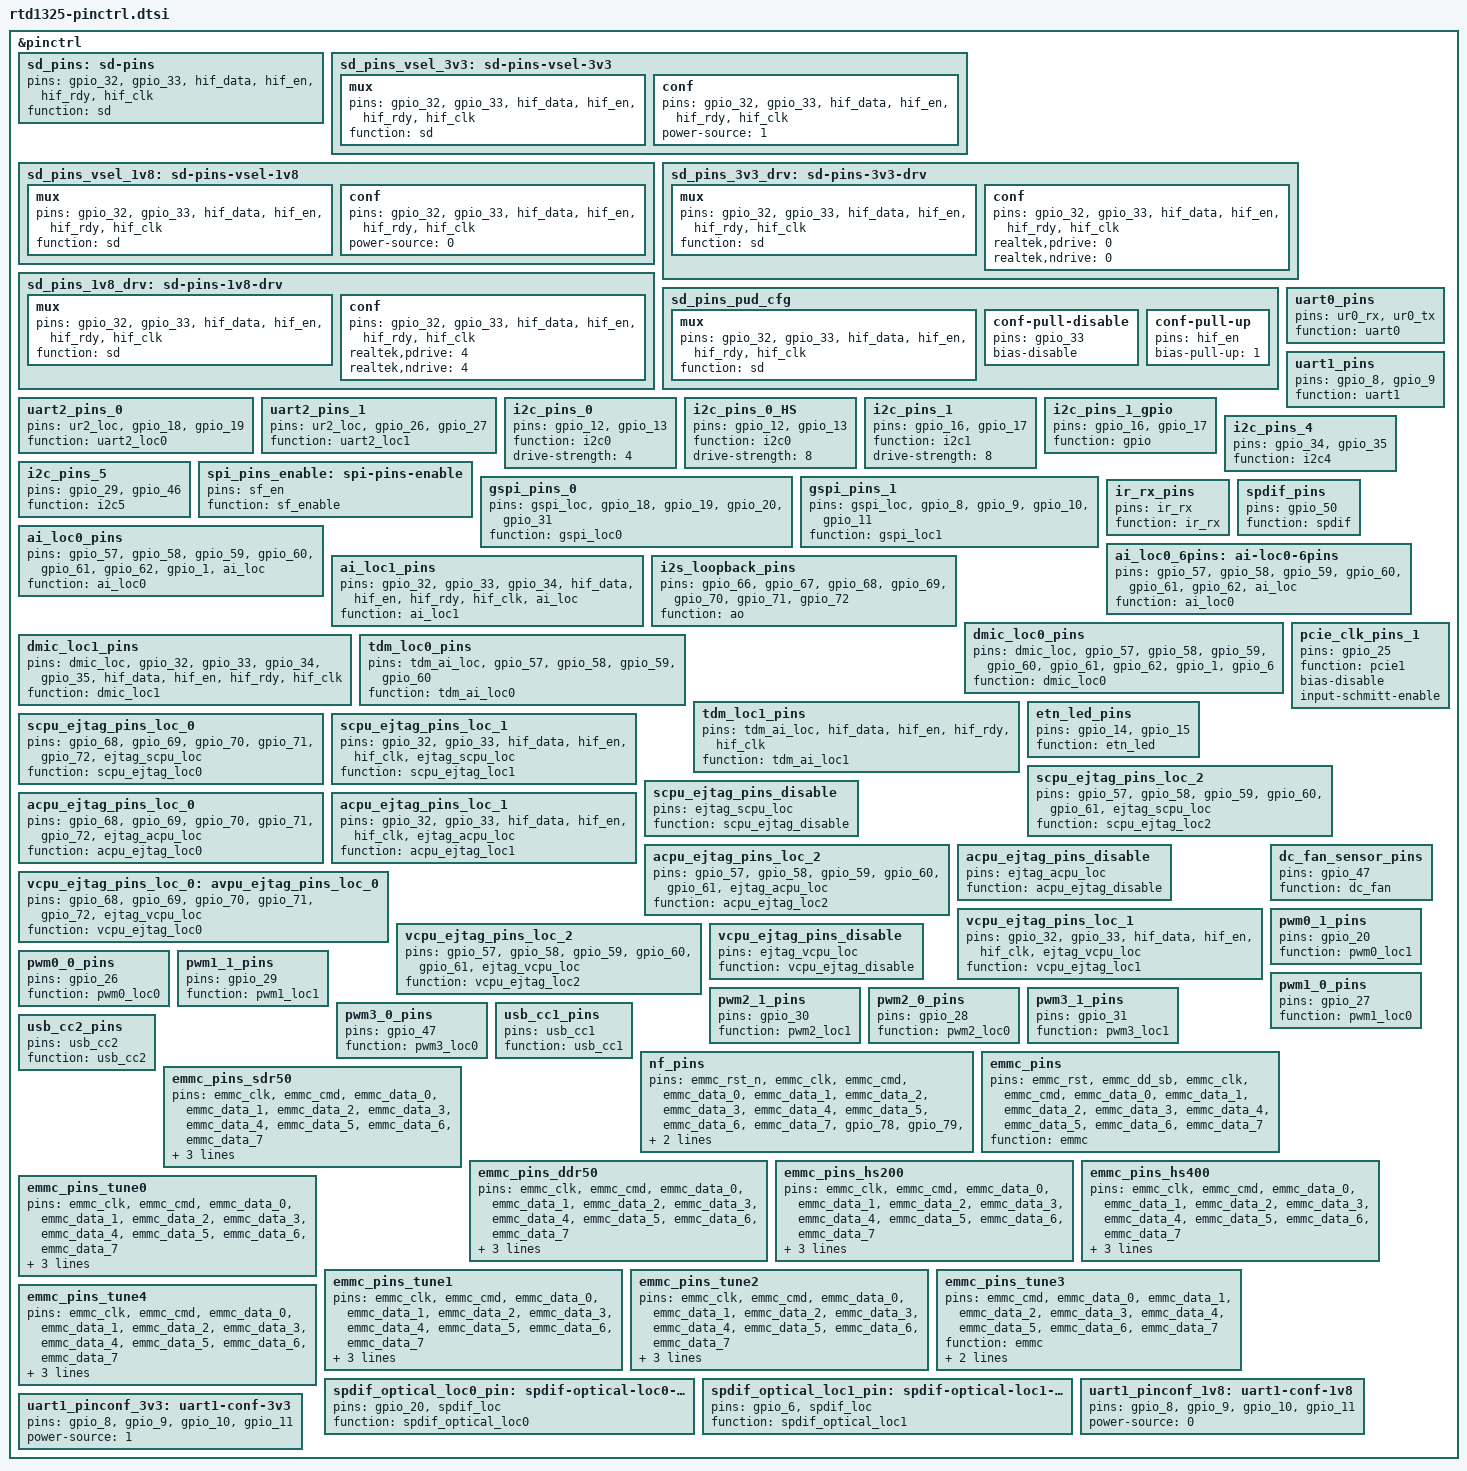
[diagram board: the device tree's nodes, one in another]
// SPDX-License-Identifier: (GPL-2.0-or-later OR BSD-2-Clause)
/*
 * Copyright (c) 2022 Realtek Semiconductor Corp.
 */

&pinctrl {
	sd_pins: sd-pins {
		pins = "gpio_32", "gpio_33", "hif_data", "hif_en", "hif_rdy", "hif_clk";
		function = "sd";
	};

	sd_pins_vsel_3v3: sd-pins-vsel-3v3 {
		mux {
			pins = "gpio_32", "gpio_33", "hif_data", "hif_en", "hif_rdy", "hif_clk";
			function = "sd";
		};

		conf {
			pins = "gpio_32", "gpio_33", "hif_data", "hif_en", "hif_rdy", "hif_clk";
			power-source = <1>;
		};
	};

	sd_pins_vsel_1v8: sd-pins-vsel-1v8 {
		mux {
			pins = "gpio_32", "gpio_33", "hif_data", "hif_en", "hif_rdy", "hif_clk";
			function = "sd";
		};

		conf {
			pins = "gpio_32", "gpio_33", "hif_data", "hif_en", "hif_rdy", "hif_clk";
			power-source = <0>;
		};
	};

	sd_pins_3v3_drv: sd-pins-3v3-drv {
		mux {
			pins = "gpio_32", "gpio_33", "hif_data", "hif_en", "hif_rdy", "hif_clk";
			function = "sd";
		};

		conf {
			pins = "gpio_32", "gpio_33", "hif_data", "hif_en", "hif_rdy", "hif_clk";
			realtek,pdrive = <0>;
			realtek,ndrive = <0>;
		};
	};

	sd_pins_1v8_drv: sd-pins-1v8-drv {
		mux {
			pins = "gpio_32", "gpio_33", "hif_data", "hif_en", "hif_rdy", "hif_clk";
			function = "sd";
		};

		conf {
			pins = "gpio_32", "gpio_33", "hif_data", "hif_en", "hif_rdy", "hif_clk";
			realtek,pdrive = <4>;
			realtek,ndrive = <4>;
		};
	};

	sd_pins_pud_cfg: sd_pins_pud_cfg {
		mux {
			pins = "gpio_32", "gpio_33", "hif_data", "hif_en", "hif_rdy", "hif_clk";
			function = "sd";
		};

		conf-pull-disable {
			pins = "gpio_33";
			bias-disable;
		};

		conf-pull-up {
			pins = "hif_en";
			bias-pull-up = <1>;
		};
	};

	uart0_pins: uart0_pins {
		pins = "ur0_rx",
			"ur0_tx";
		function = "uart0";
	};

	uart1_pins: uart1_pins {
		pins = "gpio_8",
			"gpio_9";
		function = "uart1";
	};

	uart2_pins_0: uart2_pins_0 {
		pins = "ur2_loc",
			"gpio_18",
			"gpio_19";
		function = "uart2_loc0";
	};

	uart2_pins_1: uart2_pins_1 {
		pins ="ur2_loc",
			"gpio_26",
			"gpio_27";
		function = "uart2_loc1";
	};

	i2c_pins_0: i2c_pins_0 {
		pins = "gpio_12",
			"gpio_13";
		function = "i2c0";
		drive-strength = <4>;
	};

	i2c_pins_0_HS: i2c_pins_0_HS {
		pins = "gpio_12",
			"gpio_13";
		function = "i2c0";
		drive-strength = <8>;
	};

	i2c_pins_1: i2c_pins_1 {
		pins = "gpio_16",
			"gpio_17";
		function = "i2c1";
		drive-strength = <8>;
	};

	i2c_pins_1_gpio: i2c_pins_1_gpio {
		pins = "gpio_16",
			"gpio_17";
		function = "gpio";
	};

	i2c_pins_4: i2c_pins_4 {
		pins = "gpio_34",
			"gpio_35";
		function = "i2c4";
	};

	i2c_pins_5: i2c_pins_5 {
		pins = "gpio_29",
			"gpio_46";
		function = "i2c5";
	};

	spi_pins_enable: spi-pins-enable {
		pins = "sf_en";
		function = "sf_enable";
	};

	gspi_pins_0: gspi_pins_0 {
		pins = "gspi_loc",
			"gpio_18",
			"gpio_19",
			"gpio_20",
			"gpio_31";
		function = "gspi_loc0";
	};

	gspi_pins_1: gspi_pins_1 {
		pins = "gspi_loc",
			"gpio_8",
			"gpio_9",
			"gpio_10",
			"gpio_11";
		function = "gspi_loc1";
	};

	ir_rx_pins: ir_rx_pins {
		pins = "ir_rx";
		function = "ir_rx";
	};

	spdif_pins: spdif_pins {
		pins = "gpio_50";
		function = "spdif";
	};

	ai_loc0_pins: ai_loc0_pins {
		pins = "gpio_57",
			"gpio_58",
			"gpio_59",
			"gpio_60",
			"gpio_61",
			"gpio_62",
			"gpio_1",
			"ai_loc";
		function = "ai_loc0";
	};

	ai_loc0_6pins: ai-loc0-6pins {
		pins = "gpio_57",
			"gpio_58",
			"gpio_59",
			"gpio_60",
			"gpio_61",
			"gpio_62",
			"ai_loc";
		function = "ai_loc0";
	};

	ai_loc1_pins: ai_loc1_pins {
		pins = "gpio_32",
			"gpio_33",
			"gpio_34",
			"hif_data",
			"hif_en",
			"hif_rdy",
			"hif_clk",
			"ai_loc";
		function = "ai_loc1";
	};

	i2s_loopback_pins: i2s_loopback_pins {
		pins = "gpio_66",
			"gpio_67",
			"gpio_68",
			"gpio_69",
			"gpio_70",
			"gpio_71",
			"gpio_72";
		function = "ao";
	};

	dmic_loc0_pins: dmic_loc0_pins {
		pins = "dmic_loc",
			"gpio_57",
			"gpio_58",
			"gpio_59",
			"gpio_60",
			"gpio_61",
			"gpio_62",
			"gpio_1",
			"gpio_6";
		function = "dmic_loc0";
	};

	dmic_loc1_pins: dmic_loc1_pins {
		pins = "dmic_loc",
			"gpio_32",
			"gpio_33",
			"gpio_34",
			"gpio_35",
			"hif_data",
			"hif_en",
			"hif_rdy",
			"hif_clk";
		function = "dmic_loc1";
	};

	tdm_loc0_pins: tdm_loc0_pins {
		pins = "tdm_ai_loc",
			"gpio_57",
			"gpio_58",
			"gpio_59",
			"gpio_60";
		function = "tdm_ai_loc0";
	};


	tdm_loc1_pins: tdm_loc1_pins {
		pins = "tdm_ai_loc",
			"hif_data",
			"hif_en",
			"hif_rdy",
			"hif_clk";
		function = "tdm_ai_loc1";
	};

	etn_led_pins: etn_led_pins {
		pins = "gpio_14",
			"gpio_15";
		function = "etn_led";
	};

	pcie_clk_pins_1: pcie_clk_pins_1 {
		pins = "gpio_25";
		function = "pcie1";
		bias-disable;
		input-schmitt-enable;
	};

	scpu_ejtag_pins_loc_0: scpu_ejtag_pins_loc_0 {
		pins = "gpio_68",
			"gpio_69",
			"gpio_70",
			"gpio_71",
			"gpio_72",
			"ejtag_scpu_loc";
		function = "scpu_ejtag_loc0";
	};

	scpu_ejtag_pins_loc_1: scpu_ejtag_pins_loc_1 {
		pins = "gpio_32",
			"gpio_33",
			"hif_data",
			"hif_en",
			"hif_clk",
			"ejtag_scpu_loc";
		function = "scpu_ejtag_loc1";
	};

	scpu_ejtag_pins_loc_2: scpu_ejtag_pins_loc_2 {
		pins = "gpio_57",
			"gpio_58",
			"gpio_59",
			"gpio_60",
			"gpio_61",
			"ejtag_scpu_loc";
		function = "scpu_ejtag_loc2";
	};

	scpu_ejtag_pins_disable: scpu_ejtag_pins_disable {
		pins = "ejtag_scpu_loc";
		function = "scpu_ejtag_disable";
	};

	acpu_ejtag_pins_loc_0: acpu_ejtag_pins_loc_0 {
		pins = "gpio_68",
			"gpio_69",
			"gpio_70",
			"gpio_71",
			"gpio_72",
			"ejtag_acpu_loc";
		function = "acpu_ejtag_loc0";
	};

	acpu_ejtag_pins_loc_1: acpu_ejtag_pins_loc_1 {
		pins = "gpio_32",
			"gpio_33",
			"hif_data",
			"hif_en",
			"hif_clk",
			"ejtag_acpu_loc";
		function = "acpu_ejtag_loc1";
	};

	acpu_ejtag_pins_loc_2: acpu_ejtag_pins_loc_2 {
		pins = "gpio_57",
			"gpio_58",
			"gpio_59",
			"gpio_60",
			"gpio_61",
			"ejtag_acpu_loc";
		function = "acpu_ejtag_loc2";
	};

	acpu_ejtag_pins_disable:acpu_ejtag_pins_disable{
		pins = "ejtag_acpu_loc";
		function = "acpu_ejtag_disable";
	};

	vcpu_ejtag_pins_loc_0: avpu_ejtag_pins_loc_0 {
		pins = "gpio_68",
			"gpio_69",
			"gpio_70",
			"gpio_71",
			"gpio_72",
			"ejtag_vcpu_loc";
		function = "vcpu_ejtag_loc0";
	};

	vcpu_ejtag_pins_loc_1: vcpu_ejtag_pins_loc_1 {
		pins = "gpio_32",
			"gpio_33",
			"hif_data",
			"hif_en",
			"hif_clk",
			"ejtag_vcpu_loc";
		function = "vcpu_ejtag_loc1";
	};

	vcpu_ejtag_pins_loc_2: vcpu_ejtag_pins_loc_2 {
		pins = "gpio_57",
			"gpio_58",
			"gpio_59",
			"gpio_60",
			"gpio_61",
			"ejtag_vcpu_loc";
		function = "vcpu_ejtag_loc2";
	};

	vcpu_ejtag_pins_disable:vcpu_ejtag_pins_disable{
		pins = "ejtag_vcpu_loc";
		function = "vcpu_ejtag_disable";
	};

	dc_fan_sensor_pins: dc_fan_sensor_pins {
		pins = "gpio_47";
		function = "dc_fan";
	};

	pwm0_1_pins: pwm0_1_pins {
		pins = "gpio_20";
		function = "pwm0_loc1";
	};

	pwm0_0_pins: pwm0_0_pins {
		pins = "gpio_26";
		function = "pwm0_loc0";
	};

	pwm1_1_pins: pwm1_1_pins {
		pins = "gpio_29";
		function = "pwm1_loc1";
	};

	pwm1_0_pins: pwm1_0_pins {
		pins = "gpio_27";
		function = "pwm1_loc0";
	};

	pwm2_1_pins: pwm2_1_pins {
		pins = "gpio_30";
		function = "pwm2_loc1";
	};

	pwm2_0_pins: pwm2_0_pins {
		pins = "gpio_28";
		function = "pwm2_loc0";
	};

	pwm3_1_pins: pwm3_1_pins {
		pins = "gpio_31";
		function = "pwm3_loc1";
	};

	pwm3_0_pins: pwm3_0_pins {
		pins = "gpio_47";
		function = "pwm3_loc0";
	};

	usb_cc1_pins: usb_cc1_pins {
		pins = "usb_cc1";
		function = "usb_cc1";
	};

	usb_cc2_pins: usb_cc2_pins {
		pins = "usb_cc2";
		function = "usb_cc2";
	};

	nf_pins: nf_pins {
		pins = "emmc_rst_n",
			"emmc_clk",
			"emmc_cmd",
			"emmc_data_0",
			"emmc_data_1",
			"emmc_data_2",
			"emmc_data_3",
			"emmc_data_4",
			"emmc_data_5",
			"emmc_data_6",
			"emmc_data_7",
			"gpio_78",
			"gpio_79",
			"gpio_80",
			"gpio_81";
		function = "nf";
	};
	emmc_pins: emmc_pins {
		pins = "emmc_rst",
			"emmc_dd_sb",
			"emmc_clk",
			"emmc_cmd",
			"emmc_data_0",
			"emmc_data_1",
			"emmc_data_2",
			"emmc_data_3",
			"emmc_data_4",
			"emmc_data_5",
			"emmc_data_6",
			"emmc_data_7";
		function = "emmc";
	};

	emmc_pins_sdr50: emmc_pins_sdr50 {
		pins = "emmc_clk",
			"emmc_cmd",
			"emmc_data_0",
			"emmc_data_1",
			"emmc_data_2",
			"emmc_data_3",
			"emmc_data_4",
			"emmc_data_5",
			"emmc_data_6",
			"emmc_data_7";
		function = "emmc";
		realtek,pdrive = <0x0>;
		realtek,ndrive = <0x0>;
	};
	emmc_pins_ddr50: emmc_pins_ddr50 {
		pins = "emmc_clk",
			"emmc_cmd",
			"emmc_data_0",
			"emmc_data_1",
			"emmc_data_2",
			"emmc_data_3",
			"emmc_data_4",
			"emmc_data_5",
			"emmc_data_6",
			"emmc_data_7";
		function = "emmc";
		realtek,pdrive = <0x0>;
		realtek,ndrive = <0x0>;
	};

	emmc_pins_hs200: emmc_pins_hs200 {
		pins = "emmc_clk",
			"emmc_cmd",
			"emmc_data_0",
			"emmc_data_1",
			"emmc_data_2",
			"emmc_data_3",
			"emmc_data_4",
			"emmc_data_5",
			"emmc_data_6",
			"emmc_data_7";
		function = "emmc";
		realtek,pdrive = <0x2>;
		realtek,ndrive = <0x2>;
	};

	emmc_pins_hs400: emmc_pins_hs400 {
		pins = "emmc_clk",
			"emmc_cmd",
			"emmc_data_0",
			"emmc_data_1",
			"emmc_data_2",
			"emmc_data_3",
			"emmc_data_4",
			"emmc_data_5",
			"emmc_data_6",
			"emmc_data_7";
		function = "emmc";
		realtek,pdrive = <0x4>;
		realtek,ndrive = <0x4>;
	};

	emmc_pins_tune0: emmc_pins_tune0 {
		pins = "emmc_clk",
			"emmc_cmd",
			"emmc_data_0",
			"emmc_data_1",
			"emmc_data_2",
			"emmc_data_3",
			"emmc_data_4",
			"emmc_data_5",
			"emmc_data_6",
			"emmc_data_7";
		function = "emmc";
		realtek,pdrive = <0x0>;
		realtek,ndrive = <0x0>;
	};

	emmc_pins_tune1: emmc_pins_tune1 {
		pins = "emmc_clk",
			"emmc_cmd",
			"emmc_data_0",
			"emmc_data_1",
			"emmc_data_2",
			"emmc_data_3",
			"emmc_data_4",
			"emmc_data_5",
			"emmc_data_6",
			"emmc_data_7";
		function = "emmc";
		realtek,pdrive = <0x1>;
		realtek,ndrive = <0x1>;
	};

	emmc_pins_tune2: emmc_pins_tune2 {
		pins = "emmc_clk",
			"emmc_cmd",
			"emmc_data_0",
			"emmc_data_1",
			"emmc_data_2",
			"emmc_data_3",
			"emmc_data_4",
			"emmc_data_5",
			"emmc_data_6",
			"emmc_data_7";
		function = "emmc";
		realtek,pdrive = <0x2>;
		realtek,ndrive = <0x2>;
	};

	emmc_pins_tune3: emmc_pins_tune3 {
		pins = //"emmc_clk",
			"emmc_cmd",
			"emmc_data_0",
			"emmc_data_1",
			"emmc_data_2",
			"emmc_data_3",
			"emmc_data_4",
			"emmc_data_5",
			"emmc_data_6",
			"emmc_data_7";
		function = "emmc";
		realtek,pdrive = <0x3>;
		realtek,ndrive = <0x3>;
	};

	emmc_pins_tune4: emmc_pins_tune4 {
		pins = "emmc_clk",
		       "emmc_cmd",
		       "emmc_data_0",
		       "emmc_data_1",
		       "emmc_data_2",
		       "emmc_data_3",
		       "emmc_data_4",
		       "emmc_data_5",
		       "emmc_data_6",
		       "emmc_data_7";
		function = "emmc";
		realtek,pdrive = <0x7>;
		realtek,ndrive = <0x7>;
	};

	spdif_optical_loc0_pin: spdif-optical-loc0-pin {
		pins = "gpio_20",
		       "spdif_loc";
		function = "spdif_optical_loc0";
	};

	spdif_optical_loc1_pin: spdif-optical-loc1-pin {
		pins = "gpio_6",
		       "spdif_loc";
		function = "spdif_optical_loc1";
	};

	uart1_pinconf_1v8: uart1-conf-1v8 {
		pins = "gpio_8", "gpio_9", "gpio_10", "gpio_11";
		power-source = <0>;
	};

	uart1_pinconf_3v3: uart1-conf-3v3 {
		pins = "gpio_8", "gpio_9", "gpio_10", "gpio_11";
		power-source = <1>;
	};
};

